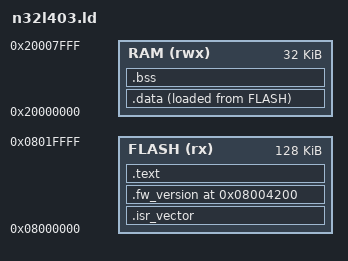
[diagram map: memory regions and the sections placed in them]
/* Application 链接脚本（有 Bootloader）
 * Flash: 48KB @ 0x08004000  (Slot A)
 * RAM:   32KB  @ 0x20000000
 */

MEMORY
{
    FLASH (rx)  : ORIGIN = 0x08000000, LENGTH = 128K
    RAM   (rwx) : ORIGIN = 0x20000000, LENGTH = 32K
}

_estack = ORIGIN(RAM) + LENGTH(RAM);

SECTIONS
{
    .isr_vector :
    {
        . = ALIGN(4);
        KEEP(*(.isr_vector))
        . = ALIGN(4);
    } > FLASH

    /* 固件版本标记，固定在 Flash 偏移 0x200 处，供 Bootloader 读取 */
    .fw_version 0x08004200 :
    {
        KEEP(*(.fw_version))
    } > FLASH

    .text :
    {
        . = ALIGN(4);
        *(.text)
        *(.text*)
        *(.rodata)
        *(.rodata*)
        KEEP(*(.init))
        KEEP(*(.fini))
        . = ALIGN(4);
        _etext = .;
    } > FLASH

    _sidata = LOADADDR(.data);

    .data :
    {
        . = ALIGN(4);
        _sdata = .;
        *(.data)
        *(.data*)
        . = ALIGN(4);
        _edata = .;
    } > RAM AT > FLASH

    .bss :
    {
        . = ALIGN(4);
        _sbss = .;
        *(.bss)
        *(.bss*)
        *(COMMON)
        . = ALIGN(4);
        _ebss = .;
    } > RAM

    /DISCARD/ :
    {
        libc.a(*)
        libm.a(*)
        libgcc.a(*)
    }
}
